AUTOSAR XML (schema 00049)
package /Application/DltConfig
  dlt log channel to process mapping DltLogChannelToProcessMapping_IntelligentWiper_TO_IntelligentWiper: dlt-log-channel=IntelligentWiper, process=IntelligentWiper
package /Application/Executable
  executable IntelligentWiper: category=APPLICATION_LEVEL, logging-behavior=USES-LOGGING, reporting-behavior=REPORTS-EXECUTION-STATE, version=1.0.0
    root sw component prototype AA: application-type=IntelligentWiper
package /Application/Manifest
  5 x service instance to port prototype mapping:
    IntelligentWiper_AA_RPort_PDW_FRONT: port-prototype=AA.RPort_PDW_FRONT, service-instance=EEVP_IntelligentWiper_Consumer_PdwFrontService
    IntelligentWiper_AA_RPort_PDW_REAR: port-prototype=AA.RPort_PDW_REAR, service-instance=EEVP_IntelligentWiper_Consumer_PdwRearService
    IntelligentWiper_AA_RPort_SubscriptionManagement: port-prototype=AA.RPort_SubscriptionManagement, service-instance=EEVP_IntelligentWiper_Consumer_SubscriptionManagement
    IntelligentWiper_AA_RPort_VehicleInfo: port-prototype=AA.RPort_VehicleInfo, service-instance=EEVP_IntelligentWiper_Consumer_SoaVehicleInfo
    IntelligentWiper_AA_RPort_Wiper: port-prototype=AA.RPort_Wiper, service-instance=EEVP_IntelligentWiper_Consumer_SoaWiper
package /Application/Process
  process IntelligentWiper: executable=IntelligentWiper, state-dependent-startup-config{function-group-state=[SFG02.On, SFG02.Verify], resource-group=DefaultResourceGroup, startup-config=DefaultStartupConfig}
    process state machine IntelligentWiper: type=ProcessState
package /Application/SwComponent
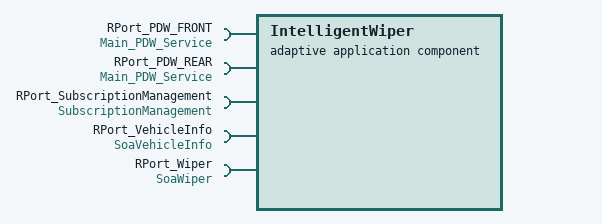
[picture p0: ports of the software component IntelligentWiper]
  adaptive application sw component type IntelligentWiper
    5 x require port:
      RPort_PDW_FRONT: required-interface=Main_PDW_Service
      RPort_PDW_REAR: required-interface=Main_PDW_Service
      RPort_SubscriptionManagement: required-interface=SubscriptionManagement
      RPort_VehicleInfo: required-interface=SoaVehicleInfo
      RPort_Wiper: required-interface=SoaWiper
